AUTOSAR XML (schema 4-2-2)
package /ASW_DEM
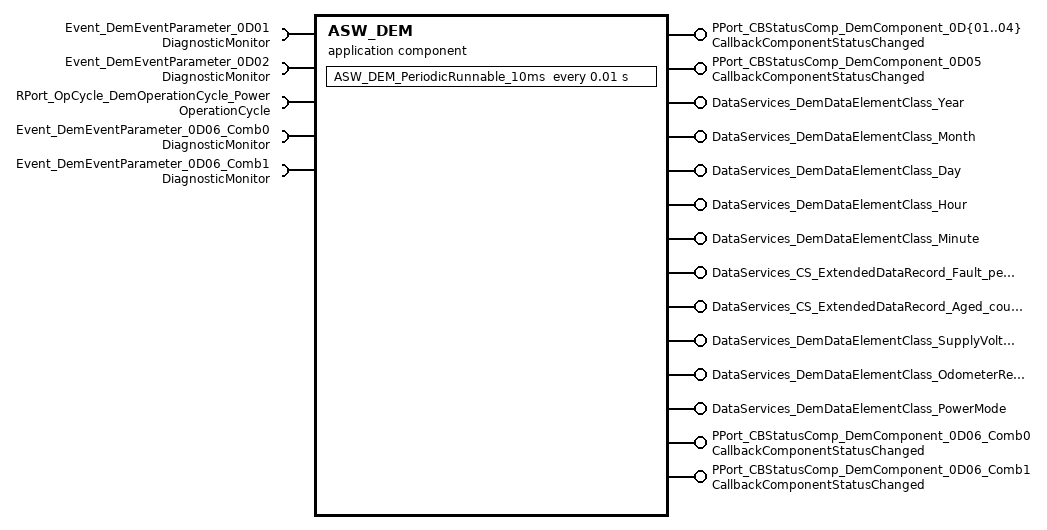
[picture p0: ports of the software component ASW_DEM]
  application sw component type ASW_DEM
    4 x provide port, all with provided-interface=CallbackComponentStatusChanged:
      PPort_CBStatusComp_DemComponent_0D{01..04}
    require port Event_DemEventParameter_0D01: required-interface=DiagnosticMonitor
    require port Event_DemEventParameter_0D02: required-interface=DiagnosticMonitor
    require port RPort_OpCycle_DemOperationCycle_Power: required-interface=OperationCycle
    13 x provide port:
      PPort_CBStatusComp_DemComponent_0D05: provided-interface=CallbackComponentStatusChanged
      DataServices_DemDataElementClass_Year: provided-interface=DataServices_DemDataElementClass_Year
      DataServices_DemDataElementClass_Month: provided-interface=DataServices_DemDataElementClass_Month
      DataServices_DemDataElementClass_Day: provided-interface=DataServices_DemDataElementClass_Day
      DataServices_DemDataElementClass_Hour: provided-interface=DataServices_DemDataElementClass_Hour
      DataServices_DemDataElementClass_Minute: provided-interface=DataServices_DemDataElementClass_Minute
      DataServices_CS_ExtendedDataRecord_Fault_pending_counter: provided-interface=DataServices_CS_ExtendedDataRecord_Fault_pending_counter
      DataServices_CS_ExtendedDataRecord_Aged_counter: provided-interface=DataServices_CS_ExtendedDataRecord_Aged_counter
      DataServices_DemDataElementClass_SupplyVoltage: provided-interface=DataServices_DemDataElementClass_SupplyVoltage
      DataServices_DemDataElementClass_OdometerReading: provided-interface=DataServices_DemDataElementClass_OdometerReading
      DataServices_DemDataElementClass_PowerMode: provided-interface=DataServices_DemDataElementClass_PowerMode
      PPort_CBStatusComp_DemComponent_0D06_Comb0: provided-interface=CallbackComponentStatusChanged
      PPort_CBStatusComp_DemComponent_0D06_Comb1: provided-interface=CallbackComponentStatusChanged
    require port Event_DemEventParameter_0D06_Comb0: required-interface=DiagnosticMonitor
    require port Event_DemEventParameter_0D06_Comb1: required-interface=DiagnosticMonitor
    behavior IB_Dem_SWC
      timing event TimingEvent_Dem_SWC: start-on-event=ASW_DEM_PeriodicRunnable_10ms, period=0.01
      17 x operation invoked event:
        OperationInvokedEvent_0: start-on-event=ASW_DEM_DataServices_DemDataElementClass_OdometerReading, operation=DataServices_DemDataElementClass_OdometerReading.ReadData
        OperationInvokedEvent_1: start-on-event=ASW_DEM_DataServices_DemDataElementClass_Day, operation=DataServices_DemDataElementClass_Day.ReadData
        OperationInvokedEvent_2: start-on-event=ASW_DEM_DataServices_CS_ExtendedDataRecord_Fault_pending_counter, operation=DataServices_CS_ExtendedDataRecord_Fault_pending_counter.ReadData
        OperationInvokedEvent_3: start-on-event=ASW_DEM_DataServices_CS_ExtendedDataRecord_Aged_counter, operation=DataServices_CS_ExtendedDataRecord_Aged_counter.ReadData
        OperationInvokedEvent_4: start-on-event=ASW_DEM_DataServices_DemDataElementClass_SupplyVoltage, operation=DataServices_DemDataElementClass_SupplyVoltage.ReadData
        OperationInvokedEvent_6: start-on-event=ASW_DEM_DataServices_DemDataElementClass_Hour, operation=DataServices_DemDataElementClass_Hour.ReadData
        OperationInvokedEvent_7: start-on-event=ASW_DEM_DataServices_DemDataElementClass_Minute, operation=DataServices_DemDataElementClass_Minute.ReadData
        OperationInvokedEvent_8: start-on-event=ASW_DEM_DataServices_DemDataElementClass_Month, operation=DataServices_DemDataElementClass_Month.ReadData
        OperationInvokedEvent_9: start-on-event=ASW_DEM_DataServices_DemDataElementClass_PowerMode, operation=DataServices_DemDataElementClass_PowerMode.ReadData
        OperationInvokedEvent_10: start-on-event=ASW_DEM_DataServices_DemDataElementClass_Year, operation=DataServices_DemDataElementClass_Year.ReadData
        OperationInvokedEvent_11: start-on-event=ASW_DEM_CBStatusComp_DemComponent, operation=PPort_CBStatusComp_DemComponent_0D01.ComponentStatusChanged
        OperationInvokedEvent_12: start-on-event=ASW_DEM_CBStatusComp_DemComponent, operation=PPort_CBStatusComp_DemComponent_0D02.ComponentStatusChanged
        OperationInvokedEvent_13: start-on-event=ASW_DEM_CBStatusComp_DemComponent, operation=PPort_CBStatusComp_DemComponent_0D05.ComponentStatusChanged
        OperationInvokedEvent_14: start-on-event=ASW_DEM_CBStatusComp_DemComponent, operation=PPort_CBStatusComp_DemComponent_0D06_Comb0.ComponentStatusChanged
        OperationInvokedEvent_15: start-on-event=ASW_DEM_CBStatusComp_DemComponent, operation=PPort_CBStatusComp_DemComponent_0D04.ComponentStatusChanged
        OperationInvokedEvent_16: start-on-event=ASW_DEM_CBStatusComp_DemComponent, operation=PPort_CBStatusComp_DemComponent_0D03.ComponentStatusChanged
        OperationInvokedEvent_17: start-on-event=ASW_DEM_CBStatusComp_DemComponent, operation=PPort_CBStatusComp_DemComponent_0D06_Comb1.ComponentStatusChanged
      12 x runnable:
        ASW_DEM_PeriodicRunnable_10ms: symbol=ASW_DEM_PeriodicRunnable_10ms_func
          28 x sync call:
            SynchronousServerCallPoint_0: operation=Event_DemEventParameter_0D01.SetEventStatus
            SynchronousServerCallPoint_1: operation=Event_DemEventParameter_0D01.SetEventStatusWithEnvdata
            SynchronousServerCallPoint_2: operation=Event_DemEventParameter_0D01.ResetEventStatus
            SynchronousServerCallPoint_3: operation=Event_DemEventParameter_0D01.PrestoreFreezeFrame
            SynchronousServerCallPoint_4: operation=Event_DemEventParameter_0D01.ClearPrestoredFreezeFrame
            SynchronousServerCallPoint_5: operation=Event_DemEventParameter_0D01.ResetEventDebounceStatus
            SynchronousServerCallPoint_10: operation=RPort_OpCycle_DemOperationCycle_Power.SetOperationCycleState
            SynchronousServerCallPoint_11: operation=RPort_OpCycle_DemOperationCycle_Power.GetOperationCycleState
            SynchronousServerCallPoint_12: operation=RPort_OpCycle_DemOperationCycle_Power.GetCycleQualified
            SynchronousServerCallPoint_13: operation=RPort_OpCycle_DemOperationCycle_Power.SetCycleQualified
            SynchronousServerCallPoint_14: operation=Event_DemEventParameter_0D06_Comb0.SetEventStatus
            SynchronousServerCallPoint_15: operation=Event_DemEventParameter_0D06_Comb0.SetEventStatusWithEnvdata
            SynchronousServerCallPoint_16: operation=Event_DemEventParameter_0D06_Comb0.ResetEventStatus
            SynchronousServerCallPoint_17: operation=Event_DemEventParameter_0D06_Comb0.PrestoreFreezeFrame
            SynchronousServerCallPoint_18: operation=Event_DemEventParameter_0D06_Comb0.ClearPrestoredFreezeFrame
            SynchronousServerCallPoint_19: operation=Event_DemEventParameter_0D06_Comb0.ResetEventDebounceStatus
            SynchronousServerCallPoint_20: operation=Event_DemEventParameter_0D02.SetEventStatus
            SynchronousServerCallPoint_21: operation=Event_DemEventParameter_0D02.SetEventStatusWithEnvdata
            SynchronousServerCallPoint_22: operation=Event_DemEventParameter_0D02.ResetEventStatus
            SynchronousServerCallPoint_23: operation=Event_DemEventParameter_0D02.PrestoreFreezeFrame
            SynchronousServerCallPoint_24: operation=Event_DemEventParameter_0D02.ClearPrestoredFreezeFrame
            SynchronousServerCallPoint_25: operation=Event_DemEventParameter_0D02.ResetEventDebounceStatus
            SynchronousServerCallPoint_26: operation=Event_DemEventParameter_0D06_Comb1.SetEventStatus
            SynchronousServerCallPoint_27: operation=Event_DemEventParameter_0D06_Comb1.SetEventStatusWithEnvdata
            SynchronousServerCallPoint_28: operation=Event_DemEventParameter_0D06_Comb1.ResetEventStatus
            SynchronousServerCallPoint_29: operation=Event_DemEventParameter_0D06_Comb1.PrestoreFreezeFrame
            SynchronousServerCallPoint_30: operation=Event_DemEventParameter_0D06_Comb1.ClearPrestoredFreezeFrame
            SynchronousServerCallPoint_31: operation=Event_DemEventParameter_0D06_Comb1.ResetEventDebounceStatus
        ASW_DEM_DataServices_DemDataElementClass_Day: symbol=ASW_DEM_DataServices_DemDataElementClass_Day_ReadData_func
        ASW_DEM_DataServices_DemDataElementClass_Hour: symbol=ASW_DEM_DataServices_DemDataElementClass_Hour_ReadData_func
        ASW_DEM_DataServices_DemDataElementClass_Minute: symbol=ASW_DEM_DataServices_DemDataElementClass_Minute_ReadData_func
        ASW_DEM_DataServices_DemDataElementClass_Month: symbol=ASW_DEM_DataServices_DemDataElementClass_Month_ReadData_func
        ASW_DEM_DataServices_DemDataElementClass_Year: symbol=ASW_DEM_DataServices_DemDataElementClass_Year_ReadData_func
        ASW_DEM_DataServices_DemDataElementClass_OdometerReading: symbol=ASW_DEM_DataServices_DemDataElementClass_OdometerReading_ReadData_func
        ASW_DEM_DataServices_DemDataElementClass_SupplyVoltage: symbol=ASW_DEM_DataServices_DemDataElementClass_SupplyVoltage_ReadData_func
        ASW_DEM_DataServices_DemDataElementClass_PowerMode: symbol=ASW_DEM_DataServices_DemDataElementClass_PowerMode_ReadData_func
        ASW_DEM_DataServices_CS_ExtendedDataRecord_Fault_pending_counter: symbol=ASW_DEM_DataServices_CS_ExtendedDataRecord_Fault_pending_counter_ReadData_func
        ASW_DEM_DataServices_CS_ExtendedDataRecord_Aged_counter: symbol=ASW_DEM_DataServices_CS_ExtendedDataRecord_Aged_counter_ReadData_func
        ASW_DEM_CBStatusComp_DemComponent: symbol=ASW_DEM_CBStatusComp_DemComponent_func
